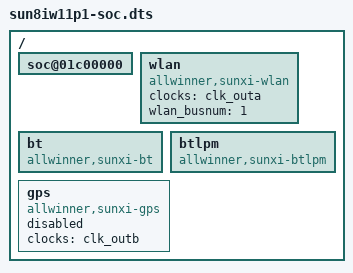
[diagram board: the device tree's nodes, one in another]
/*
 * Allwinner Technology CO., Ltd. sun8iw11p1 soc board.
 *
 */

/dts-v1/;

#include "sun8iw11p1.dtsi"

/{

	soc@01c00000 {
	};

	wlan:wlan {
		compatible = "allwinner,sunxi-wlan";
		clocks = <&clk_outa>;
		wlan_busnum = <1>;
		status = "okay";
	};

	bt:bt {
		compatible = "allwinner,sunxi-bt";
		status = "okay";
	};

	btlpm:btlpm {
		compatible = "allwinner,sunxi-btlpm";
		status = "okay";
	};

        gps:gps {
                compatible = "allwinner,sunxi-gps";
                clocks = <&clk_outb>;
                status = "disabled";
        };
};
